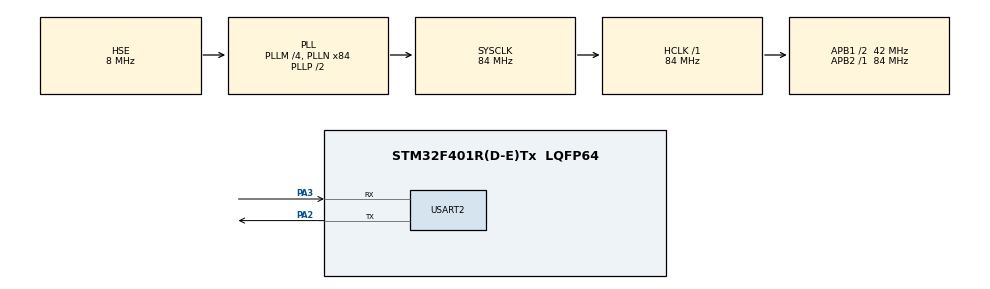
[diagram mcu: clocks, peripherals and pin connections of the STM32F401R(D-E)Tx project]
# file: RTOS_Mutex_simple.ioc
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FREERTOS.Tasks01=defaultTask,0,128,StartDefaultTask,Default,NULL,Dynamic,NULL,NULL
Mcu.Family=STM32F4
Mcu.Name=STM32F401R(D-E)Tx
Mcu.Package=LQFP64
NVIC.PriorityGroup=NVIC_PRIORITYGROUP_4
NVIC.TIM1_BRK_TIM9_IRQn=true\:0\:0\:false\:false\:true\:false\:false\:true
NVIC.TimeBase=TIM1_BRK_TIM9_IRQn
NVIC.TimeBaseIP=TIM9
NVIC.USART2_IRQn=true\:5\:0\:false\:false\:true\:true\:true\:true
PA2.Mode=Asynchronous
PA2.Signal=USART2_TX
PA3.Mode=Asynchronous
PA3.Signal=USART2_RX
PH0\ -\ OSC_IN.Mode=HSE-External-Oscillator
PH0\ -\ OSC_IN.Signal=RCC_OSC_IN
PH1\ -\ OSC_OUT.Mode=HSE-External-Oscillator
PH1\ -\ OSC_OUT.Signal=RCC_OSC_OUT
ProjectManager.HeapSize=0x200
ProjectManager.StackSize=0x400
ProjectManager.TargetToolchain=STM32CubeIDE
RCC.48MHZClocksFreq_Value=42000000
RCC.AHBFreq_Value=84000000
RCC.APB1CLKDivider=RCC_HCLK_DIV2
RCC.APB1Freq_Value=42000000
RCC.APB1TimFreq_Value=84000000
RCC.APB2Freq_Value=84000000
RCC.APB2TimFreq_Value=84000000
RCC.CortexFreq_Value=84000000
RCC.HCLKFreq_Value=84000000
RCC.HSE_VALUE=8000000
RCC.HSI_VALUE=16000000
RCC.LSE_VALUE=32768
RCC.PLLM=4
RCC.PLLN=84
RCC.PLLSourceVirtual=RCC_PLLSOURCE_HSE
RCC.SYSCLKFreq_VALUE=84000000
RCC.SYSCLKSource=RCC_SYSCLKSOURCE_PLLCLK
RCC.VCOOutputFreq_Value=168000000
USART2.VirtualMode=VM_ASYNC
VP_FREERTOS_VS_CMSIS_V1.Mode=CMSIS_V1
VP_SYS_VS_tim9.Mode=TIM9
board=custom

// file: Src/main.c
/* USER CODE BEGIN Header */
/**
  ******************************************************************************
  * @file           : main.c
  * @brief          : Main program body
  ******************************************************************************
  * @attention
  *
  * <h2><center>&copy; Copyright (c) 2021 STMicroelectronics.
  * All rights reserved.</center></h2>
  *
  * This software component is licensed by ST under Ultimate Liberty license
  * SLA0044, the "License"; You may not use this file except in compliance with
  * the License. You may obtain a copy of the License at:
  *                             www.st.com/SLA0044
  *
  ******************************************************************************
  */
/* USER CODE END Header */
#include "main.h"

#include "FreeRTOS.h"
#include "task.h"
#include "timers.h"
#include "queue.h"
#include "semphr.h"
#include "event_groups.h"

#include "stdio.h"
#include "string.h"
/* USER CODE BEGIN Includes */

#define inheritance    1
#define inversion      0

/* USER CODE END Includes */

UART_HandleTypeDef huart2;
TaskHandle_t HPT;
TaskHandle_t MPT;
TaskHandle_t LPT;

SemaphoreHandle_t mutex;
SemaphoreHandle_t binsemaphore;

void SystemClock_Config(void);
static void MX_GPIO_Init(void);
static void MX_USART2_UART_Init(void);

/* USER CODE BEGIN PFP */

void HPTask(void * argument);
void MPTask(void * argument);
void LPTask(void * argument);

/* USER CODE END PFP */

/* USER CODE BEGIN 0 */

//for priority inversion

#if inversion == 1
void send_uart(char *ptr){
	xSemaphoreTake(binsemaphore,portMAX_DELAY);
	HAL_Delay(5000);
	HAL_UART_Transmit(&huart2, ptr, strlen(ptr), HAL_MAX_DELAY);
	xSemaphoreGive(binsemaphore);
}
#endif

//for priority inheritance
#if inheritance == 1
void send_uart(char *ptr){
	xSemaphoreTake(mutex,portMAX_DELAY);
	HAL_Delay(5000);
	HAL_UART_Transmit(&huart2, ptr, strlen(ptr), HAL_MAX_DELAY);
	xSemaphoreGive(mutex);

}
#endif
/* USER CODE END 0 */

int main(void)
{

  /* MCU Configuration--------------------------------------------------------*/

  /* Reset of all peripherals, Initializes the Flash interface and the Systick. */
  HAL_Init();

  /* Configure the system clock */
  SystemClock_Config();

  /* Initialize all configured peripherals */
  MX_GPIO_Init();
  MX_USART2_UART_Init();
  /* USER CODE BEGIN 2 */
/********************Mutex  and semaphore create***************************************/
  mutex= xSemaphoreCreateMutex();
  if(mutex!=NULL){
	  HAL_UART_Transmit(&huart2, "create mutex\r\n", 15, HAL_MAX_DELAY);
  }

  binsemaphore= xSemaphoreCreateBinary();
  if(binsemaphore!=NULL){
	  HAL_UART_Transmit(&huart2, "\n create Semaphore\r\n", 15, HAL_MAX_DELAY);
  }

    xSemaphoreGive(binsemaphore);

  xTaskCreate(HPTask, "HTP", 128, 0, 3, &HPT);
  xTaskCreate(LPTask, "LTP", 128, 0, 1, &LPT);
  xTaskCreate(MPTask, "MTP", 128, 0, 2, &MPT);

  /* USER CODE END 2 */
  /* Start scheduler */
  vTaskStartScheduler();

  /* We should never get here as control is now taken by the scheduler */
  /* Infinite loop */
  while (1)
  {

  }
}

void SystemClock_Config(void)
{
  RCC_OscInitTypeDef RCC_OscInitStruct = {0};
  RCC_ClkInitTypeDef RCC_ClkInitStruct = {0};

  /** Configure the main internal regulator output voltage
  */
  __HAL_RCC_PWR_CLK_ENABLE();
  __HAL_PWR_VOLTAGESCALING_CONFIG(PWR_REGULATOR_VOLTAGE_SCALE2);
  /** Initializes the RCC Oscillators according to the specified parameters
  * in the RCC_OscInitTypeDef structure.
  */
  RCC_OscInitStruct.OscillatorType = RCC_OSCILLATORTYPE_HSE;
  RCC_OscInitStruct.HSEState = RCC_HSE_ON;
  RCC_OscInitStruct.PLL.PLLState = RCC_PLL_ON;
  RCC_OscInitStruct.PLL.PLLSource = RCC_PLLSOURCE_HSE;
  RCC_OscInitStruct.PLL.PLLM = 4;
  RCC_OscInitStruct.PLL.PLLN = 84;
  RCC_OscInitStruct.PLL.PLLP = RCC_PLLP_DIV2;
  RCC_OscInitStruct.PLL.PLLQ = 4;
  if (HAL_RCC_OscConfig(&RCC_OscInitStruct) != HAL_OK)
  {
    Error_Handler();
  }
  /** Initializes the CPU, AHB and APB buses clocks
  */
  RCC_ClkInitStruct.ClockType = RCC_CLOCKTYPE_HCLK|RCC_CLOCKTYPE_SYSCLK
                              |RCC_CLOCKTYPE_PCLK1|RCC_CLOCKTYPE_PCLK2;
  RCC_ClkInitStruct.SYSCLKSource = RCC_SYSCLKSOURCE_PLLCLK;
  RCC_ClkInitStruct.AHBCLKDivider = RCC_SYSCLK_DIV1;
  RCC_ClkInitStruct.APB1CLKDivider = RCC_HCLK_DIV2;
  RCC_ClkInitStruct.APB2CLKDivider = RCC_HCLK_DIV1;

  if (HAL_RCC_ClockConfig(&RCC_ClkInitStruct, FLASH_LATENCY_2) != HAL_OK)
  {
    Error_Handler();
  }
}

static void MX_USART2_UART_Init(void)
{

  huart2.Instance = USART2;
  huart2.Init.BaudRate = 115200;
  huart2.Init.WordLength = UART_WORDLENGTH_8B;
  huart2.Init.StopBits = UART_STOPBITS_1;
  huart2.Init.Parity = UART_PARITY_NONE;
  huart2.Init.Mode = UART_MODE_TX_RX;
  huart2.Init.HwFlowCtl = UART_HWCONTROL_NONE;
  huart2.Init.OverSampling = UART_OVERSAMPLING_16;
  if (HAL_UART_Init(&huart2) != HAL_OK)
  {
    Error_Handler();
  }

}

static void MX_GPIO_Init(void)
{

  /* GPIO Ports Clock Enable */
  __HAL_RCC_GPIOH_CLK_ENABLE();
  __HAL_RCC_GPIOA_CLK_ENABLE();

}

void HPTask(void * argument){
	char *data="HPT...........................\r\n";
	while(1){
		char *str= "\nEnter HPT \r\n";
		HAL_UART_Transmit(&huart2, str, strlen(str), HAL_MAX_DELAY);

		send_uart(data);

		char *str1= "Exit HPT \r\n\n\n";
		HAL_UART_Transmit(&huart2, str1, strlen(str1), HAL_MAX_DELAY);

		vTaskDelay(750);
	}
}

void MPTask(void * argument){

		while(1){

			char *str="MPT...........................\r\n";
			HAL_UART_Transmit(&huart2, str, strlen(str), HAL_MAX_DELAY);

			vTaskDelay(2000);

		}

}

void LPTask(void * argument){

		char *data="LPT...........................\r\n";
		while(1){
			char *str= "Enter LPT \r\n";
			HAL_UART_Transmit(&huart2, str, strlen(str), HAL_MAX_DELAY);

			send_uart(data);

			char *str1= "Exit LPT \r\n\n\n";
			HAL_UART_Transmit(&huart2, str1, strlen(str1), HAL_MAX_DELAY);

			vTaskDelay(1000);
		}

}
 /**
  * @brief  Period elapsed callback in non blocking mode
  * @note   This function is called  when TIM9 interrupt took place, inside
  * HAL_TIM_IRQHandler(). It makes a direct call to HAL_IncTick() to increment
  * a global variable "uwTick" used as application time base.
  * @param  htim : TIM handle
  * @retval None
  */
void HAL_TIM_PeriodElapsedCallback(TIM_HandleTypeDef *htim)
{
  if (htim->Instance == TIM9) {
    HAL_IncTick();
  }
}

void Error_Handler(void)
{
  __disable_irq();
  while (1)
  {
  }
}

/************************ (C) COPYRIGHT STMicroelectronics *****END OF FILE****/
